# A34L71x register map
Vendor: ABOV Semiconductor Co., Ltd.; File version: 1.0
CPU: CM4 r0p1, little endian, MPU, FPU, VTOR, 4 interrupt priority bits
Registers are 32-bit, read-write, reset 0x0 unless marked. A register's access mark holds for its fields unless they carry their own. Offsets are from the block's base; [hi:lo] are bit positions; {n}, {i} and the like mark numbered series.

## I2C — Inter-Integrated Circuit
Base 0x5000A000
Same registers: I2C0 0x4000A000, I2C1 0x4000A100
0x00 DR reset 0xFF — I2C data register
  [7:0] ICDR — In transmit mode, the data stored in this register is outputted from pin SDA in the serial data line. In receive mode, data received at pin SDA is stored in this register; hence, the stored data is loaded by reading this register
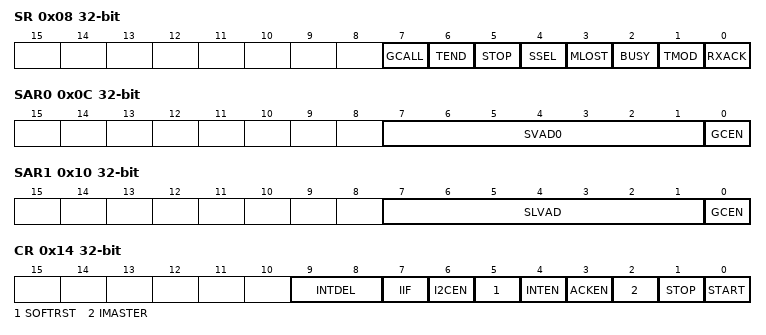
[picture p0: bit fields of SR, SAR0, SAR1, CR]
0x08 SR — 2C status register
  [7] GCALL — This bit signifies different things, depending on whether the I2C is in master or slave mode.
  [6] TEND — One-byte transmit end flag
  [5] STOP — Stop flag
  [4] SSEL — Slave flag
  [3] MLOST — Mastership loss flag
  [2] BUSY — Bus busy flag
  [1] TMOD ro — Transmit / receive mode flag
  [0] RXACK — Rx ACK flag
0x0C SAR0 — I2C slave address register 0
  [7:1] SVAD0 — 7-bit slave address
  [0] GCEN — Whether to enable or disable general call
0x10 SAR1 — I2C slave address register 1
  [7:1] SLVAD — 7-bit slave address
  [0] GCEN — Whether to enable or disable general call
0x14 CR — I2C Control Register
  [9:8] INTDEL — Internal delay between address and data transfers (Or between two data transfers)
    0=1_ICnSCLL (Delay = 1*ICnSCLL); 1=2_ICnSCLL (Delay = 2*ICnSCLL); 2=4_ICnSCLL (Delay = 4*ICnSCLL); 3=8_ICnSCLL (Delay = 8*ICnSCLL)
  [7] IIF ro — Interrupt flag
  [6] I2CEN — I2C Enable bit
  [5] SOFTRST — Software Reset allow bit
  [4] INTEN — Whether to enable or disable interrupts
  [3] ACKEN — Whether to enable or disable ACK in receive mode
  [2] IMASTER ro — Master mode flag
    0=Slave mode; 1=Master mode
  [1] STOP — Whether to enable or disable stop
  [0] START — Transmission start in master mode
0x18 SCLL reset 0xFFFF — I2C SCL low duration register
  [15:0] SCLL — SCL low duration value
0x1C SCLH reset 0xFFFF — I2C SCL high duration register
  [15:0] SCLH — SCL high duration value
0x20 SDH reset 0x7FFF — I2C SDA hold register
  [14:0] SDH — SDA hold time value

## LPUARTn — Low Power UART 0
Base 0x50008C00
Same registers: LPUART0 0x40008C00, LPUART1 0x40008D00
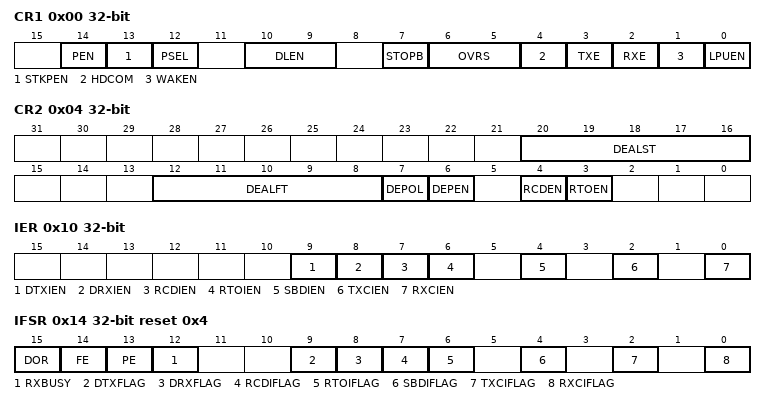
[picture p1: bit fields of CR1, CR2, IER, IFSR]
0x00 CR1 — LPUARTn Control Register 1
  [14] PEN — Parity Enable
  [13] STKPEN — Stick Parity Enable
  [12] PSEL — Parity Selection
  [10:9] DLEN — Data Length Selection
  [7] STOPB — Stop bit
  [6:5] OVRS — Oversampling Selection
  [4] HDCOM — 1-wire Half-Duplex Communication
  [3] TXE — Enable the transmitter unit.
  [2] RXE — Enable the receiver unit.
  [1] WAKEN — Wake-Up Function bit in Deep Sleep Mode
  [0] LPUEN — Low Power UART Enable
0x04 CR2 — LPUARTn Control Register 2
  [20:16] DEALST — DE Pin Active Level Start Time
  [12:8] DEALFT — DE Pin Active Level Finish Time
  [7] DEPOL — DE Pin Polarity Selection
  [6] DEPEN — DE Pin Function Enable
  [4] RCDEN — Receive Character Detection Function Enable
  [3] RTOEN — Receive Time Out Function Enable
0x10 IER — LPUARTn Interrupt Enable Register
  [9] DTXIEN — Whether to enable or disable the DMA transmit complete interrupt
  [8] DRXIEN — Whether to enable or disable the DMA receive complete interrupt
  [7] RCDIEN — Receive Character Detection Interrupt Enable
  [6] RTOIEN — Receive Time Out Interrupt Enable
  [4] SBDIEN — Start Bit Detection Interrupt Enable bit in Deep Sleep Mode
  [2] TXCIEN — Transmit Complete Interrupt Enable
  [0] RXCIEN — Receive Data Register Not Empty Interrupt Enable
0x14 IFSR reset 0x4 — LPUARTn Interrupt Flag and Status Register
  [15] DOR — Data Overrun
  [14] FE — Frame Error
  [13] PE — Parity Error
  [12] RXBUSY ro — RXD Line Busy
  [9] DTXFLAG — DMA transmit complete interrupt Flag
  [8] DRXFLAG — DMA receive complete interrupt Flag
  [7] RCDIFLAG — Receive Character detection Interrupt Flag
  [6] RTOIFLAG — Receive Time Out Interrupt Flag
  [4] SBDIFLAG — Start Bit Detection Interrupt Flag
  [2] TXCIFLAG — Transmit Complete Interrupt Flag
  [0] RXCIFLAG — Receive Data Register Not Empty Interrupt Flag
0x18 RDR ro — LPUARTn Receive Data Register
  [7:0] RDATA — Receive Data
0x1C TDR — LPUARTn Transmit Data Register
  [7:0] TDATA — Transmit Data
0x20 BDR reset 0xFFFF — LPUARTn Baud Rate Data Register
  [15:0] BDATA — These bits are used to generate baud rate
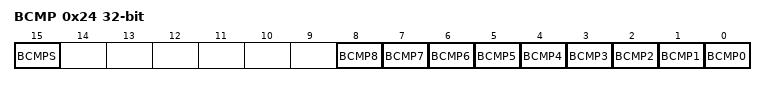
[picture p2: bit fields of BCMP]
0x24 BCMP — LPUARTn Baud Rate Compensation Register
  [15] BCMPS — Baud Rate Compensation Sign
  [n] BCMP{n} (n=0..8) — Baud Rate Compensation {n}
0x28 RTODR reset 0xFFFF — LPUARTn Receive Time Out Data Register
  [23:0] RTOD — LPUARTn Receive Time Out Data
0x2C RCDR — LPUARTn Receive Character Detection Data Register
  [7:0] RCDD — LPUARTn Receive Character Detection Data
0x30 DLYDR — LPUARTn Tx Delay Time Data Register
  [7:0] DLYD — LPUARTn Tx Delay Data
